# AM13E230x register map
Vendor: Texas Instruments; File version: Revised: 2025-12-26 17:30:06
CPU: CM33 r0p0, little endian, MPU, FPU, 4 interrupt priority bits
Registers are 32-bit, read-write, reset 0x0 unless marked. A register's access mark holds for its fields unless they carry their own. Offsets are from the block's base; [hi:lo] are bit positions; lines under a group give offsets from that group; {n}, {i} and the like mark numbered series.

## INPUTXBAR — INPUT_XBAR_REGS
Base 0x40468000
{0x0+4i} INPUTSELECT[{i}] (i=0..27) reset 0xFE — Input Select Register (GPIO0 to x)
  [7:0] SELECT — Select GPIO for INPUT{#} signal
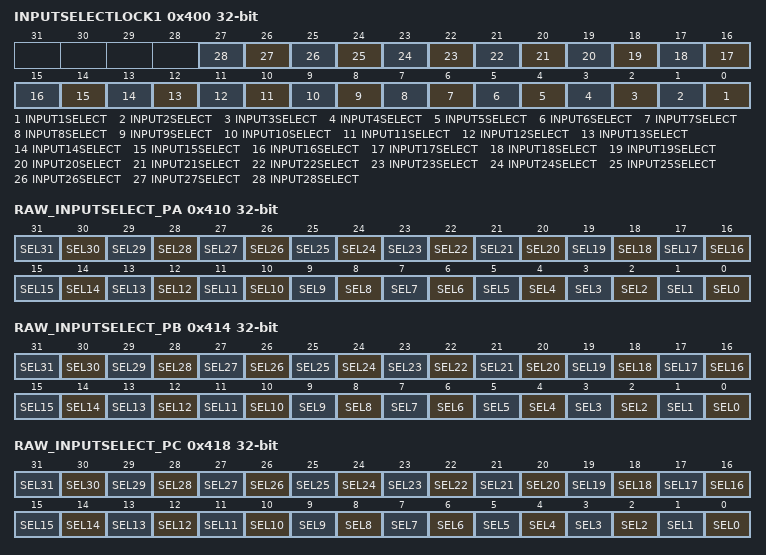
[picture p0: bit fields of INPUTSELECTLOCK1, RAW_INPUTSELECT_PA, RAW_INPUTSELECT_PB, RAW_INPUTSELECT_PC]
0x400 INPUTSELECTLOCK1 — Input Select Lock Register 1
  [n-1] INPUT{n}SELECT (n=1..28) — Lock bit for INPUT{n}SELECT Register
0x410 RAW_INPUTSELECT_PA — Raw Input Select Register for Port-A GPIOs
  [n] SEL{n} (n=0..31) — Raw input select bit for PA{n}
0x414 RAW_INPUTSELECT_PB — Raw Input Select Register for Port-B GPIOs
  [n] SEL{n} (n=0..31) — Raw input select bit for PB{n}
0x418 RAW_INPUTSELECT_PC — Raw Input Select Register for Port-C GPIOs
  [n] SEL{n} (n=0..31) — Raw input select bit for PC{n}
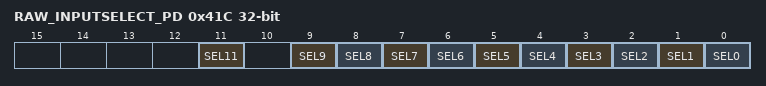
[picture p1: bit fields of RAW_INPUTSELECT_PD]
0x41C RAW_INPUTSELECT_PD — Raw Input Select Register for Port-D GPIOs
  [11] SEL11 — Raw input select bit for PD11
  [n] SEL{n} (n=0..9) — Raw input select bit for PD{n}

## OUTPUTXBAR0_FLAGS — OUTPUTXBAR_FLAG_REGS
Base 0x40470000
Same registers: OUTPUTXBAR1_FLAGS 0x40471000, OUTPUTXBAR2_FLAGS 0x40472000, OUTPUTXBAR3_FLAGS 0x40473000, OUTPUTXBAR4_FLAGS 0x40474000, OUTPUTXBAR5_FLAGS 0x40475000, OUTPUTXBAR6_FLAGS 0x40476000, OUTPUTXBAR7_FLAGS 0x40477000
0x10 OUTPUTXBARSTATUS — Output Signal Status register
  [0] STS ro — Output Signal Status
0x18 OUTPUTXBARFLAG — Output latched flag register
  [0] FLG ro — Output Signal Latched Flag Status
0x1C OUTPUTXBARFLAGCLEAR — Output latched flag clear register
  [0] FLG — Output Signal Latched Flag Clear
0x20 OUTPUTXBARFLAGFORCE — Output latched flag Force register
  [0] FLG — Output Signal Latched Flag Force

## OUTPUTXBAR — OUTPUTXBAR_REGS
Base 0x4046A000
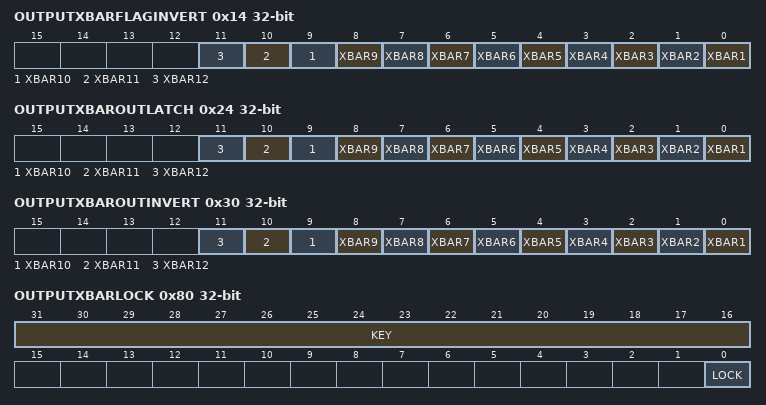
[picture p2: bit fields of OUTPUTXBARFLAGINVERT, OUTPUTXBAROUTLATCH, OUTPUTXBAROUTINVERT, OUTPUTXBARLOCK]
0x14 OUTPUTXBARFLAGINVERT — Output Signal inversion register
  [n-1] XBAR{n} (n=1..12) — Invert XBAR Output Before Latch for XBAR{n}
0x24 OUTPUTXBAROUTLATCH — Output Signal Select Latch
  [n-1] XBAR{n} (n=1..12) — XBAR Output Latch Select for XBAR{n}
0x30 OUTPUTXBAROUTINVERT — Output Signal Invert Select
  [n-1] XBAR{n} (n=1..12) — Invert XBAR Output for XBAR{n}
0x80 OUTPUTXBARLOCK — Configuration Lock register
  [31:16] KEY wo — Write key: the write only takes effect if KEY is 0x5A5A
    0x5A5A=UNLOCK (Bit 0 of this register can be set only if KEY = 0x5A5A)
  [0] LOCK — Locks the configuration for EOUTPUT-XBAR
{0x100+8i} OUTPUTXBAR_REGS_REGISTERFILE0[{i}] (i=0..11) group
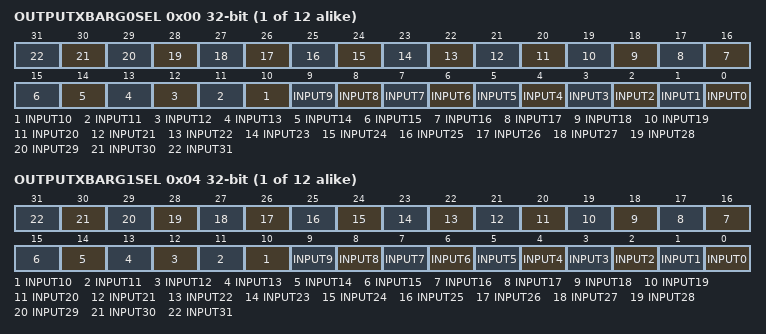
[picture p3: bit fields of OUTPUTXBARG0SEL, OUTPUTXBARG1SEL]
  0x00 OUTPUTXBARG0SEL — OUTPUTXBAR G0 Input Select
    [n] INPUT{n} (n=0..31) — Select bit for INPUT{n}
  0x04 OUTPUTXBARG1SEL — OUTPUTXBAR G1 Input Select
    [n] INPUT{n} (n=0..31) — Select bit for INPUT{n}

## SYNC_SOC — SYNC_SOC_REGS
Base 0x4046B000
0x00 SYNCSELECT — Sync Input and Output Select Register
  [28:24] SYNCOUT — Select EXT Syncout Source
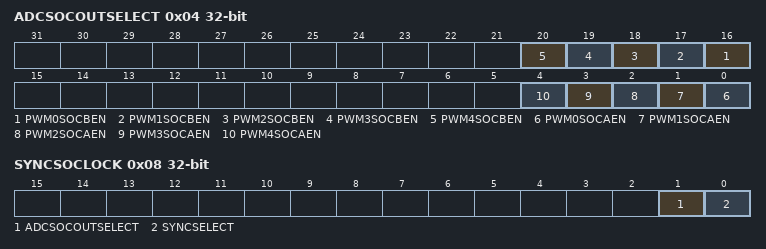
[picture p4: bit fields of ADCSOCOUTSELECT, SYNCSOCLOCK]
0x04 ADCSOCOUTSELECT — External ADCSOC Select Register
  [n+16] PWM{n}SOCBEN (n=0..4) — PWM{n}SOCBEN Enable for ADCSOCBOn
  [n] PWM{n}SOCAEN (n=0..4) — PWM{n}SOCAEN Enable for ADCSOCAOn
0x08 SYNCSOCLOCK — SYNCSEL and EXTADCSOC Select Lock register
  [1] ADCSOCOUTSELECT — ADCSOCOUTSELECT Register Lock bit
  [0] SYNCSELECT — SYNCSEL Register Lock bit

## PWMXBAR — EPWM_XBAR_REGS
Base 0x40469000
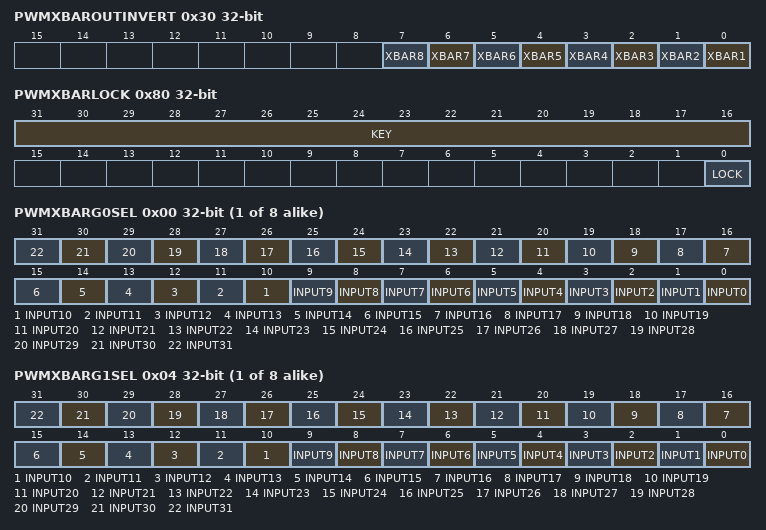
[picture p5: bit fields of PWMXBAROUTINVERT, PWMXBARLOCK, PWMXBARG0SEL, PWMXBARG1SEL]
0x30 PWMXBAROUTINVERT — Output Signal Invert Select
  [n-1] XBAR{n} (n=1..8) — Invert XBAR Output Select for XBAR{n}
0x80 PWMXBARLOCK — Configuration Lock register
  [31:16] KEY wo — Write key: the write only takes effect if KEY is 0x5A5A
    0x5A5A=UNLOCK (Bit 0 of this register can be set only if KEY = 0x5A5A)
  [0] LOCK — Locks the configuration for EPWM-XBAR
{0x100+8i} EPWM_XBAR_REGS_REGISTERFILE0[{i}] (i=0..7) group
  0x00 PWMXBARG0SEL — PWMXBAR G0 Input Select
    [n] INPUT{n} (n=0..31) — Select bit for INPUT{n}
  0x04 PWMXBARG1SEL — PWMXBAR G1 Input Select
    [n] INPUT{n} (n=0..31) — Select bit for INPUT{n}
